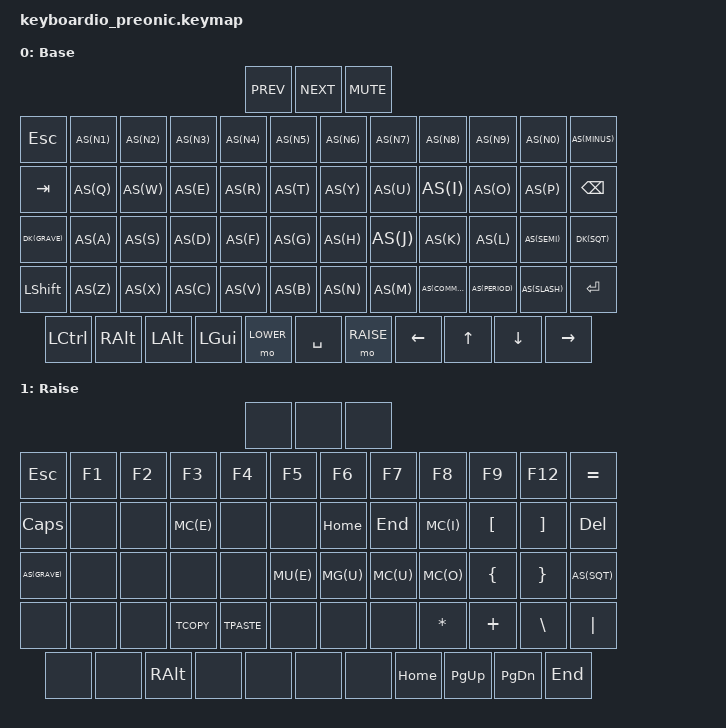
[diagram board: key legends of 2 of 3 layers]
/*
 * Copyright (c) 2022 Pete Johanson
 *
 * SPDX-License-Identifier: MIT
 */

#include <behaviors.dtsi>
#include <dt-bindings/zmk/keys.h>
#include <dt-bindings/zmk/bt.h>
#include <dt-bindings/zmk/outputs.h>
#include <dt-bindings/zmk/rgb.h>

#define LOWER 2
#define RAISE 1


// Using layer taps on thumbs, having quick tap as well helps w/ repeating space/backspace
&lt { quick_tap_ms = <200>; };

// Convenience macro to make the Bluetooth commands shorter
#define BT(n) BT_SEL n

// Hyper key: all the modifiers
#define HYPER LC(LS(LA(LGUI)))
// Define copy paster in terminal
#define TCOPY LC(LS(C))
#define TPASTE LC(LS(V))

// define autoshift feature
#define AS(keycode) &as LS(keycode) keycode
// Dead key for Windows US-Intl: key + SPACE gives the literal char (tap: ', hold: ")
#define DK(keycode) &dk LS(keycode) keycode
#define MA(keycode) &m_accent_cir SQT keycode
#define MG(keycode) &m_accent_cir GRAVE keycode
#define MC(keycode) &m_accent_cir LS(N6) keycode
#define MU(keycode) &m_accent_cir LS(DQT) keycode
/ {
    chosen {
        // Valid choices: [ &mit_layout, &ortho_layout ]
        zmk,physical-layout = &mit_layout;
    };


    behaviors {
            #include "macros.dtsi"
            as: auto_shift {
                compatible = "zmk,behavior-hold-tap";
                label = "AUTO_SHIFT";
                #binding-cells = <2>;
                tapping_term_ms = <170>;
                quick_tap_ms = <0>;
                flavor = "tap-preferred";
                bindings = <&kp>, <&kp>;
            };

            dk_space: dk_space {
                compatible = "zmk,behavior-macro-one-param";
                #binding-cells = <1>;
                bindings
                    = <&macro_param_1to1>
                    , <&macro_tap &kp MACRO_PLACEHOLDER>
                    , <&macro_tap &kp SPACE>;
            };

            dk: dead_key {
                compatible = "zmk,behavior-hold-tap";
                #binding-cells = <2>;
                tapping_term_ms = <170>;
                quick_tap_ms = <0>;
                flavor = "tap-preferred";
                bindings = <&dk_space>, <&dk_space>;
            };

        };






    keymap {
        compatible = "zmk,keymap";

        base_layer {
            label = "Base";
            bindings = <
                                                                                                             &kp K_PREV    &kp K_NEXT      &kp C_MUTE

 &kp ESC   AS(N1)      AS(N2)      AS(N3)      AS(N4)      AS(N5)      AS(N6)      AS(N7)      AS(N8)      AS(N9)      AS(N0)      AS(MINUS)
 &kp TAB     AS(Q)       AS(W)       AS(E)       AS(R)       AS(T)       AS(Y)       AS(U)       AS(I)       AS(O)       AS(P)       &kp BKSP
 DK(GRAVE)     AS(A)       AS(S)       AS(D)       AS(F)       AS(G)       AS(H)       AS(J)       AS(K)      AS(L)       AS(SEMI)    DK(SQT)
 &kp LSHFT   AS(Z)       AS(X)       AS(C)       AS(V)       AS(B)        AS(N)       AS(M)       AS(COMMA)   AS(PERIOD)  AS(SLASH)   &kp ENTER
 &kp LCTRL   &kp RALT   &kp LALT    &kp LGUI    &mo LOWER         &kp SPACE         &mo RAISE   &kp LEFT    &kp UP    &kp DOWN      &kp RIGHT

            >;
            sensor-bindings = <&inc_dec_kp C_VOLUME_UP C_VOLUME_DOWN>;
        };

        raise_layer {
            label = "Raise";
            bindings = <
                                                                                                               &none     &none     &none

 &kp ESC     &kp F1      &kp F2      &kp F3      &kp F4      &kp F5      &kp F6      &kp F7       &kp F8       &kp F9     &kp F12    &kp EQUAL
 &kp CAPS      &none      &none      MC(E)      &none      &none      &kp HOME    &kp END MC(I) &kp LBKT   &kp RBKT   &kp DEL
 AS(GRAVE)    &none      &none   &none      &none      MU(E)      MG(U)    MC(U)     MC(O)       &kp LEFT_BRACE  &kp RIGHT_BRACE     AS(SQT)
 &none      &none      &none      &kp TCOPY    &kp TPASTE      &none      &none      &none       &kp STAR       &kp PLUS     &kp BACKSLASH     &kp PIPE
 &none      &none      &kp RALT    &none      &none            &none            &none       &kp HOME       &kp PG_UP     &kp PG_DN   &kp END

            >;
            sensor-bindings = <&inc_dec_kp C_VOLUME_UP C_VOLUME_DOWN>;
        };

        func_layer {
            label = "Function";
            bindings = <
                                                                                                             &none      &none      &none

 &out OUT_TOG &kp F1   &kp F2   &kp F3   &kp F4   &kp F5   &kp F6      &kp F7      &kp F8     &kp F9      &kp F10      &kp F11
 &none       &bt BT(0)   &bt BT(1)   &bt BT(2)   &bt BT(3)   &bt BT(4)      &bt BT_CLR      &none      &none     &none      &bt BT_CLR_ALL       &kp F12
 AS(GRAVE)       MG(A)      MC(A)      MC(E)      MA(E)      MG(E)      &kp HOME      &kp INS      &none     &none      &none      AS(SQT)
 &none       &m_line_sel      &none      &kp TCOPY    &kp TPASTE      &none      &none      &none      &none     &none      &none      &none
 &sys_reset  &none      &none      &none      &studio_unlock    &none             &none       &kp HOME       &kp PG_UP     &kp PG_DN    &kp END

            >;
            sensor-bindings = <&inc_dec_kp C_VOLUME_UP C_VOLUME_DOWN>;
        };
    };
};
